# PIC32CZ4010CA91208 device description
Architecture: CORTEX-M7; Family: PIC32C; Series: PIC32CZCA91
Registers are 32-bit, read-write, reset 0x0 unless marked. A register's access mark holds for its fields unless they carry their own. Offsets are from the block's base; [hi:lo] are bit positions; {n}, {i} and the like mark numbered series.

## FUSES_CALOTP — Defines FUSE parameters
Instances: FUSES_CALOTP 0x0A007000
0x180 FCCFG64 ro reset not defined — PTC Calibration
  [15:0] PTCFG0
0x184 FCCFG65 ro reset not defined — ADC Calibration
  [31:0] ADCFG0
0x188 FCCFG66 ro reset not defined — Comparator Calibration
  [7:0] ACPAIR_SEL
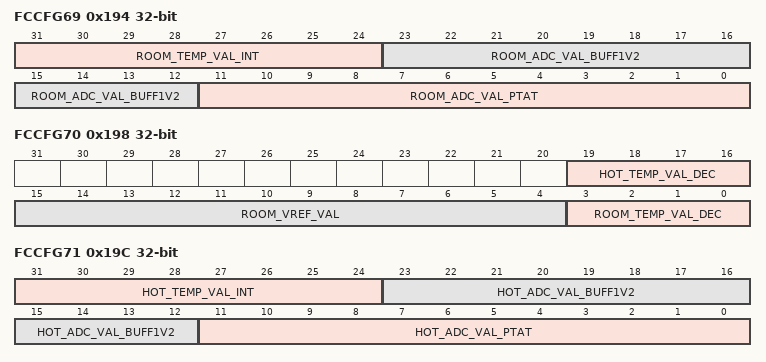
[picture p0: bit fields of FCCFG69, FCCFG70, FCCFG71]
0x194 FCCFG69 ro reset not defined — Temperature calibration values 0
  [31:24] ROOM_TEMP_VAL_INT, [23:12] ROOM_ADC_VAL_BUFF1V2, [11:0] ROOM_ADC_VAL_PTAT
0x198 FCCFG70 ro reset not defined — Temperature calibration values 1
  [19:16] HOT_TEMP_VAL_DEC, [15:4] ROOM_VREF_VAL, [3:0] ROOM_TEMP_VAL_DEC
0x19C FCCFG71 ro reset not defined — Temperature calibration values 2
  [31:24] HOT_TEMP_VAL_INT, [23:12] HOT_ADC_VAL_BUFF1V2, [11:0] HOT_ADC_VAL_PTAT
0x1A0 FCCFG72 ro reset not defined — MAC ID (31 through 0)
  [31:0] FMAC_31_0
0x1A4 FCCFG73 ro reset not defined — MAC ID (47 through 32)
  [15:0] FMAC_47_32
{0x1E0+4i} FCCFG_UNIQID[{i}] (i=0..3) ro reset not defined — Factory programed Unique ID
  [31:0] UID — Unique ID (programmed at factory)

## FUSES_DALCFG — Defines FUSE parameters
Instances: FUSES_DALCFG 0x0A004000
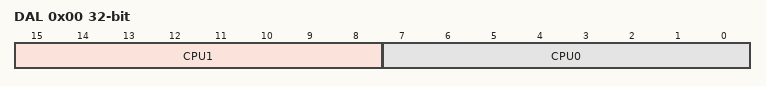
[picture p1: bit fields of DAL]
0x00 DAL — Debug Access Level
  [15:8] CPU1 — HSM DAL Elevation Value
    129=DAL0; 153=DAL1; 219=DAL2
  [7:0] CPU0 — Host DAL Elevation Value
    129=DAL0 (FCW_DAL0_VALUE); 153=DAL1 (FCW_DAL1_VALUE); 219=DAL2 (FCW_DAL2_VALUE)

## FUSES_USERCFG1 — Defines FUSE parameters
Instances: FUSES_USERCFG1 0x0A000000, FUSES_USERCFG2 0x0A008000
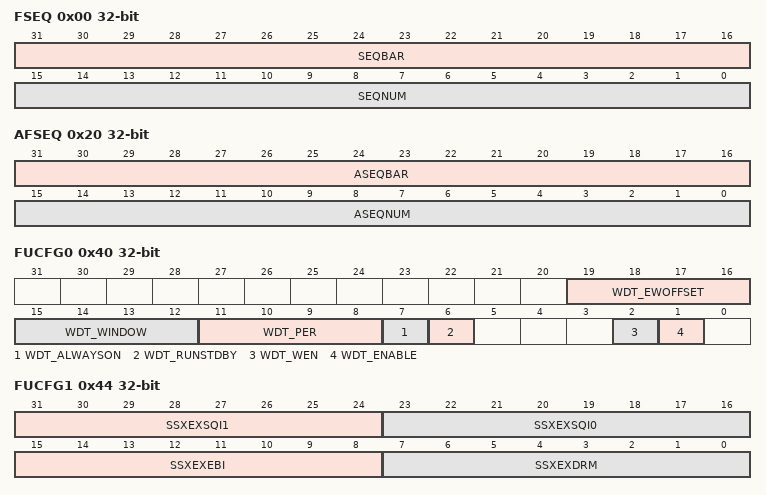
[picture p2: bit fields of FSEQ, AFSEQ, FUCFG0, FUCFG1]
0x00 FSEQ reset not defined — Flash Sequence Number
  [31:16] SEQBAR — Sequence Number Bar (Negeated)
  [15:0] SEQNUM — Sequence Number
0x20 AFSEQ reset not defined — Flash Alternate Sequence Number
  [31:16] ASEQBAR — Alternate Sequence Number Bar (Negeated)
  [15:0] ASEQNUM — Alternate Sequence Number
0x40 FUCFG0 reset not defined — WDT Configuration
  [19:16] WDT_EWOFFSET — Early Warning Interrupt Time Offset
  [15:12] WDT_WINDOW — Window Mode Time-out Period
  [11:8] WDT_PER — Time-out Period
  [7] WDT_ALWAYSON — Always On
  [6] WDT_RUNSTDBY — Run in Standby
  [2] WDT_WEN — Window Mode Enable
  [1] WDT_ENABLE — Enable
0x44 FUCFG1 reset not defined — User Configuration 1 (System Bus Configuration)
  [31:24] SSXEXSQI1 — Execute from SQI1 XIP Memory
  [23:16] SSXEXSQI0 — Execute from SQI0 XIP Memory
  [15:8] SSXEXEBI — Execute from EBI attached Memory
  [7:0] SSXEXDRM — Execute from System Memory
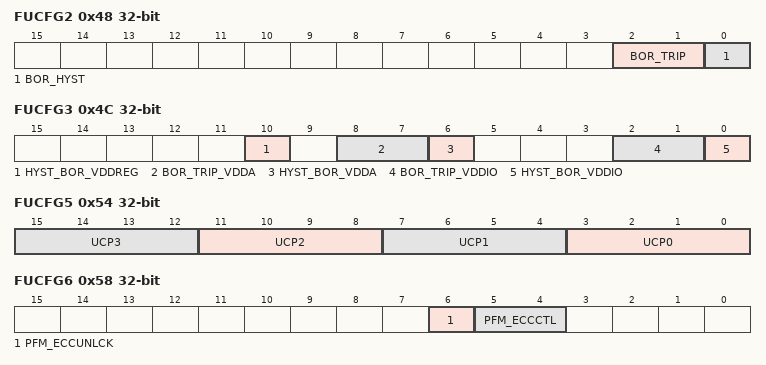
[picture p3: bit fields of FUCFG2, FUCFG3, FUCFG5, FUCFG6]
0x48 FUCFG2 reset not defined — User Configuration 2 (Deep Sleep SMOR Configuration)
  [2:1] BOR_TRIP — BOT Trip Points
  [0] BOR_HYST — BOT Trip Hystersis
0x4C FUCFG3 reset not defined — User Configuration 2 (SMOR Configuration)
  [10] HYST_BOR_VDDREG — BOR Trip Point Hystersis for VDDREG
  [8:7] BOR_TRIP_VDDA — BOR Trip Points for VDDANA
  [6] HYST_BOR_VDDA — BOR Trip Point Hystersis for VDDANA
  [2:1] BOR_TRIP_VDDIO — BOR Trip Points for VDDIO
  [0] HYST_BOR_VDDIO — BOR Trip Point Hystersis for VDDIO
0x54 FUCFG5 — User Configuration 5 (VREG Charge Pump Configuration)
  [4n+3:4n] UCP{n} (n=0..3) — Charge Pump Settings
0x58 FUCFG6 reset not defined — User Configuration 6 (FCR ECCCTRL Configuration)
  [6] PFM_ECCUNLCK — ECC Mode Control Unlock
  [5:4] PFM_ECCCTL — ECC Mode Control
0x5C FUCFG7 reset not defined — User Configuration 7 (FCR CTRLB Configuration)
  [1] PFM_TEMP — NVM Operating Temperature Read Mode
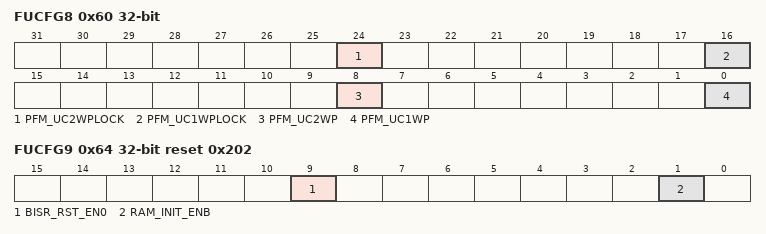
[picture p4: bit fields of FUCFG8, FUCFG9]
0x60 FUCFG8 reset not defined — User Configuration 8 (FCW CWP Configuration)
  [24] PFM_UC2WPLOCK — User Configuration Page 2 Write Protection Lock
  [16] PFM_UC1WPLOCK — User Configuration Page 1 Write Protection Lock
  [8] PFM_UC2WP — User Configuration Page 2 Write Protect
  [0] PFM_UC1WP — User Configuration Page 1 Write Protect
0x64 FUCFG9 reset 0x202 — User Configuration 9 (RAM BISR and ECC Configuraiton)
  [9] BISR_RST_EN0 — Enable RAM Built-In Self Repair at Reset
  [1] RAM_INIT_ENB — Enable RAM ECC Init at Reset
0x80 FUCFG16 reset not defined — User Configuration 16 (HSM Firmware Metadata 0 Address)
  [31:0] HSM_PTRMETA0 — HSM Firmware Metadata pointer 0
0xA0 FUCFG24 reset not defined — User Configuration 24 (HSM Firmware Metadata 1 Address)
  [31:0] HSM_PTRMETA1 — HSM Firmware Metadata pointer 1
